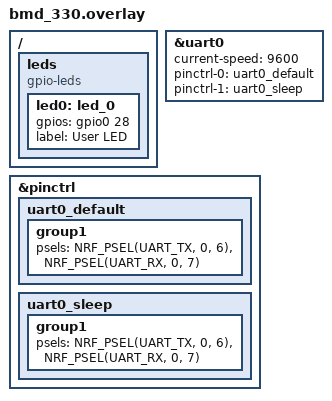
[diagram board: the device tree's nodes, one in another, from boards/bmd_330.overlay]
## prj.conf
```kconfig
CONFIG_GPIO=y
CONFIG_SERIAL=y
CONFIG_CONSOLE=y
CONFIG_UART_CONSOLE=y
CONFIG_PRINTK=y
CONFIG_LOG=y
CONFIG_LOG_MODE_DEFERRED=y
CONFIG_CLOCK_CONTROL_NRF_K32SRC_RC=y
```

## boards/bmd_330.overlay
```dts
/* bmd_330.overlay */

&uart0 {
    current-speed = <9600>;
    status = "okay";
    pinctrl-0 = <&uart0_default>;
    pinctrl-1 = <&uart0_sleep>;
    pinctrl-names = "default", "sleep";
};

&pinctrl {
    uart0_default: uart0_default {
        group1 {
            psels = <NRF_PSEL(UART_TX, 0, 6)>, <NRF_PSEL(UART_RX, 0, 7)>;
        };
    };

    uart0_sleep: uart0_sleep {
        group1 {
            psels = <NRF_PSEL(UART_TX, 0, 6)>, <NRF_PSEL(UART_RX, 0, 7)>;
        };
    };
};

/ {
    leds {
        compatible = "gpio-leds";
        led0: led_0 {
            gpios = <&gpio0 28 GPIO_ACTIVE_HIGH>; 
            label = "User LED";
        };
    };
};
```

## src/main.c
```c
#include <zephyr/kernel.h>
#include <zephyr/device.h>
#include <zephyr/drivers/gpio.h>
#include <zephyr/logging/log.h>

LOG_MODULE_REGISTER(main);

#define LED_NODE DT_ALIAS(led0)
const struct gpio_dt_spec led = GPIO_DT_SPEC_GET(LED_NODE, gpios);

int main(void)
{
    if (!device_is_ready(led.port)) {
        LOG_ERR("LED GPIO port not ready");
        return 1;
    }

    if (gpio_pin_configure_dt(&led, GPIO_OUTPUT_ACTIVE) < 0) {
        LOG_ERR("Failed to configure LED pin");
        return 1;
    }

    while (1) {
        gpio_pin_toggle_dt(&led);
		LOG_INF("Hello World");
        k_msleep(1000);
    }

    return 0;
}
```
